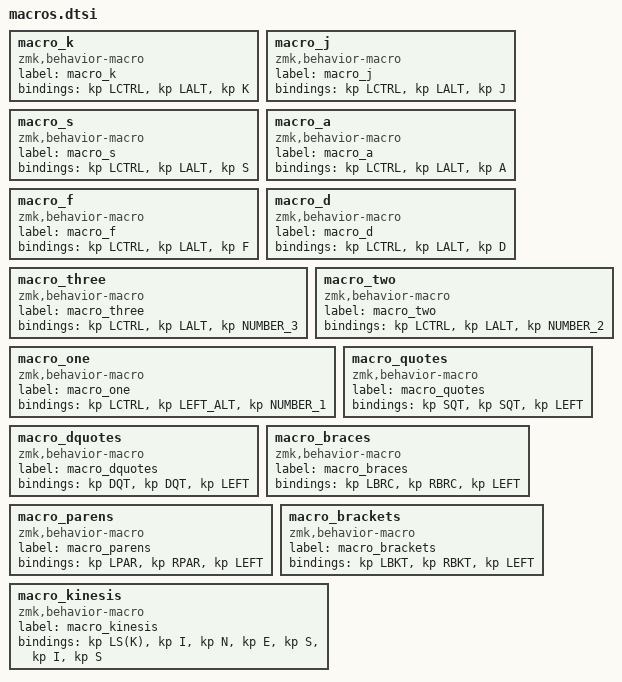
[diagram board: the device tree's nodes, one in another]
macro_k: macro_k{
compatible = "zmk,behavior-macro";
label = "macro_k";
#binding-cells = <0>;
bindings = <&kp LCTRL>, <&kp LALT>, <&kp K>;
};
macro_j: macro_j{
compatible = "zmk,behavior-macro";
label = "macro_j";
#binding-cells = <0>;
bindings = <&kp LCTRL>, <&kp LALT>, <&kp J>;
};
macro_s: macro_s{
compatible = "zmk,behavior-macro";
label = "macro_s";
#binding-cells = <0>;
bindings = <&kp LCTRL>, <&kp LALT>, <&kp S>;
};
macro_a: macro_a{
compatible = "zmk,behavior-macro";
label = "macro_a";
#binding-cells = <0>;
bindings = <&kp LCTRL>, <&kp LALT>, <&kp A>;
};
macro_f: macro_f{
compatible = "zmk,behavior-macro";
label = "macro_f";
#binding-cells = <0>;
bindings = <&kp LCTRL>, <&kp LALT>, <&kp F>;
};
macro_d: macro_d{
compatible = "zmk,behavior-macro";
label = "macro_d";
#binding-cells = <0>;
bindings = <&kp LCTRL>, <&kp LALT>, <&kp D>;
};
macro_three: macro_three{
compatible = "zmk,behavior-macro";
label = "macro_three";
#binding-cells = <0>;
bindings = <&kp LCTRL>, <&kp LALT>, <&kp NUMBER_3>;
};
macro_two: macro_two{
compatible = "zmk,behavior-macro";
label = "macro_two";
#binding-cells = <0>;
bindings = <&kp LCTRL>, <&kp LALT>, <&kp NUMBER_2>;
};
macro_one: macro_one{
compatible = "zmk,behavior-macro";
label = "macro_one";
#binding-cells = <0>;
bindings = <&kp LCTRL>, <&kp LEFT_ALT>, <&kp NUMBER_1>;
};
macro_quotes: macro_quotes{
compatible = "zmk,behavior-macro";
label = "macro_quotes";
#binding-cells = <0>;
bindings = <&kp SQT>, <&kp SQT>, <&kp LEFT>;
};
macro_dquotes: macro_dquotes{
compatible = "zmk,behavior-macro";
label = "macro_dquotes";
#binding-cells = <0>;
bindings = <&kp DQT>, <&kp DQT>, <&kp LEFT>;
};
macro_braces: macro_braces{
compatible = "zmk,behavior-macro";
label = "macro_braces";
#binding-cells = <0>;
bindings = <&kp LBRC>, <&kp RBRC>, <&kp LEFT>;
};
macro_parens: macro_parens{
compatible = "zmk,behavior-macro";
label = "macro_parens";
#binding-cells = <0>;
bindings = <&kp LPAR>, <&kp RPAR>, <&kp LEFT>;
};
macro_brackets: macro_brackets{
compatible = "zmk,behavior-macro";
label = "macro_brackets";
#binding-cells = <0>;
bindings = <&kp LBKT>, <&kp RBKT>, <&kp LEFT>;
};
macro_kinesis: macro_kinesis{
compatible = "zmk,behavior-macro";
label = "macro_kinesis";
#binding-cells = <0>;
bindings = <&kp LS(K)>, <&kp I>, <&kp N>, <&kp E>, <&kp S>, <&kp I>, <&kp S>;
};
